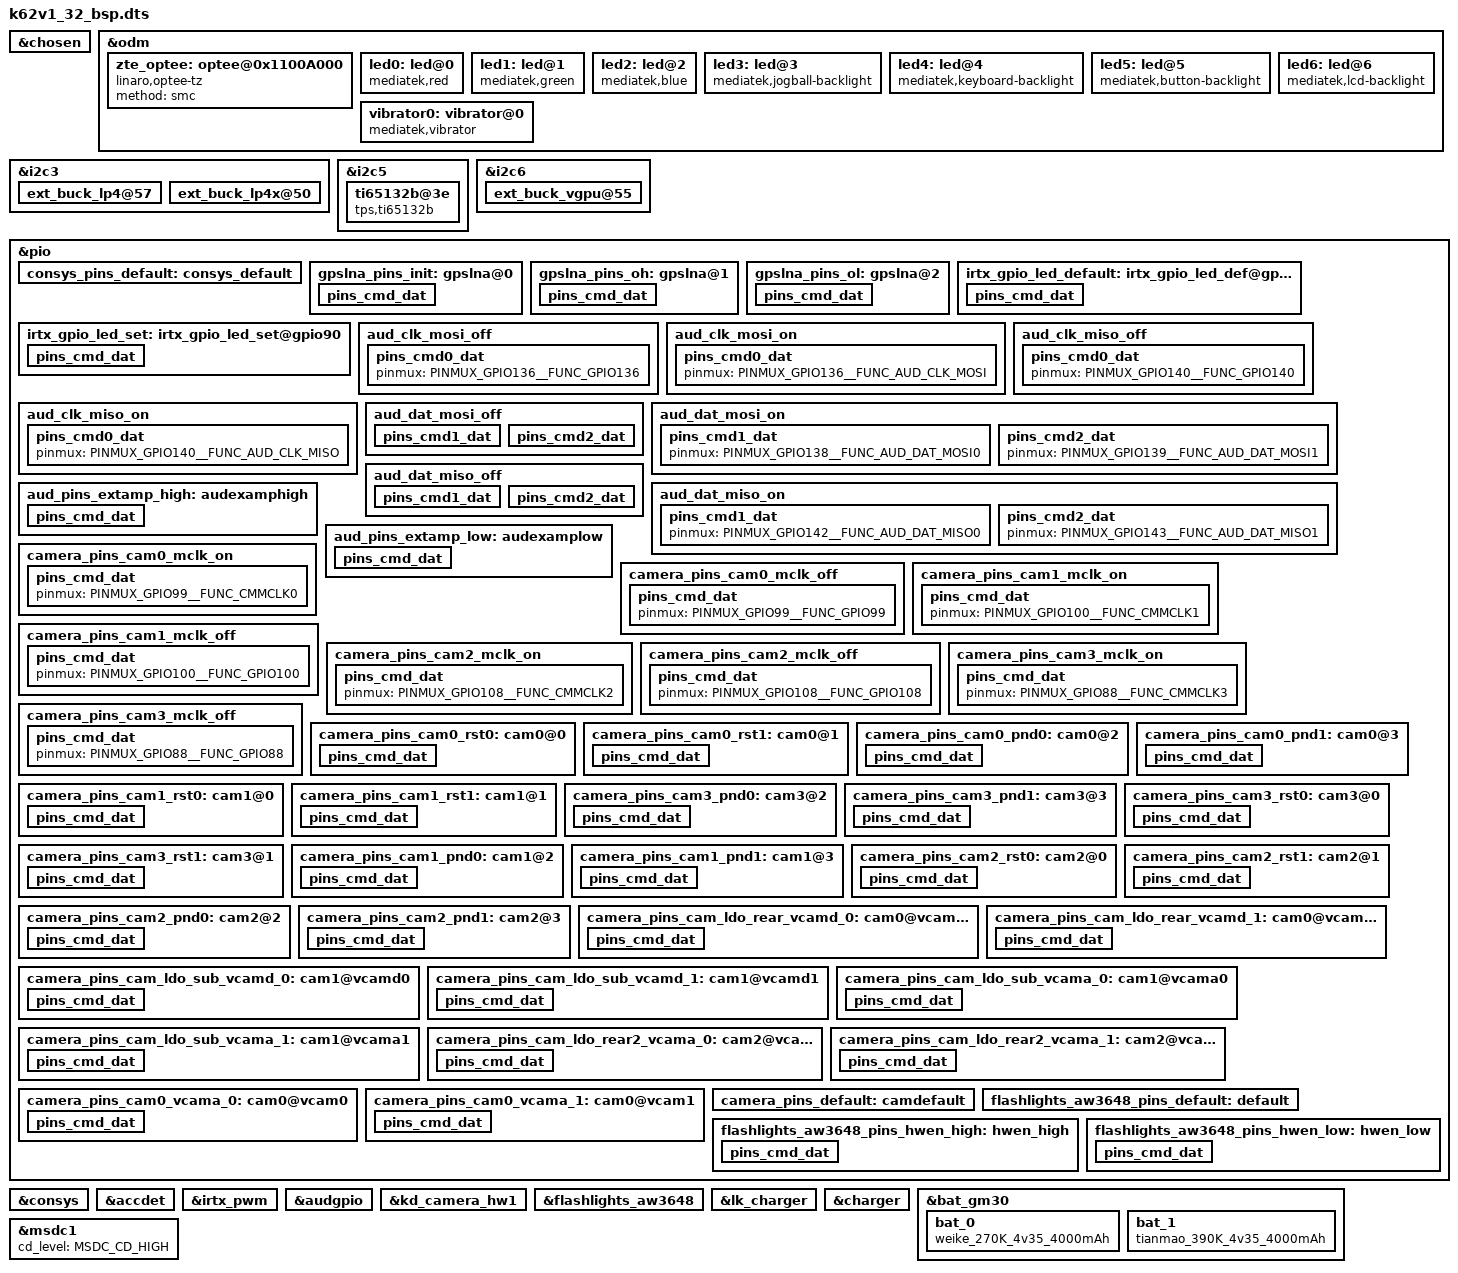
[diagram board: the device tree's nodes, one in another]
#include <dt-bindings/interrupt-controller/arm-gic.h>
#include <dt-bindings/interrupt-controller/irq.h>
#include <dt-bindings/pinctrl/mt6765-pinfunc.h>
#include <dt-bindings/mmc/mt6765-msdc.h>
#include <dt-bindings/clock/mt6765-clk.h>

/dts-v1/;
/plugin/;

#include "touchscreen_scorpio.dtsi"

/* chosen */
&chosen {

	/* fpga may has no lk, we need to specify display info here */
	/* fb buffer is reserved using this dts by memory node above */
	atag,videolfb-fb_base_h = <0x0>;
	atag,videolfb-fb_base_l = <0x5e605000>;
	atag,videolfb-islcmfound = <1>;
	/* because no lk, so lcm is not inited */
	atag,videolfb-islcm_inited = <0>;
	atag,videolfb-fps= <6000>;
	atag,videolfb-vramSize= <0x017bb000>;
	atag,videolfb-lcmname= "nt35695B_fhd_dsi_cmd_auo_rt5081_drv";
};

&odm {
	zte_optee: optee@0x1100A000 {
		compatible = "linaro,optee-tz";
		method = "smc";
	};
	led0:led@0 {
		compatible = "mediatek,red";
		led_mode = <3>;
		data = <2>;
		pwm_config = <0 0 0 0 0>;
	};
	led1:led@1 {
		compatible = "mediatek,green";
		led_mode = <3>;
		data = <1>;
		pwm_config = <0 0 0 0 0>;
	};
	led2:led@2 {
		compatible = "mediatek,blue";
		led_mode = <0>;
		data = <1>;
		pwm_config = <0 0 0 0 0>;
	};
	led3:led@3 {
		compatible = "mediatek,jogball-backlight";
		led_mode = <0>;
		data = <1>;
		pwm_config = <0 0 0 0 0>;
	};
	led4:led@4 {
		compatible = "mediatek,keyboard-backlight";
		led_mode = <0>;
		data = <1>;
		pwm_config = <0 0 0 0 0>;
	};
	led5:led@5 {
		compatible = "mediatek,button-backlight";
		led_mode = <0>;
		data = <1>;
		pwm_config = <0 0 0 0 0>;
	};
	led6:led@6 {
		compatible = "mediatek,lcd-backlight";
		led_mode = <5>;
		data = <1>;
		pwm_config = <3 0 0 0 0>;
	};
	vibrator0:vibrator@0 {
		compatible = "mediatek,vibrator";
		vib_timer = <25>;
		vib_limit = <9>;
		vib_vol= <9>;



	};
};

&i2c3 {
	ext_buck_lp4@57 {
		regulator-name ="ext_buck_vdd2";
		regulator-min-microvolt = <300000>;
		regulator-max-microvolt = <1300000>;
		vsel_pin = <0>;
	};

	ext_buck_lp4x@50 {
		regulator-name ="ext_buck_vddq";
		regulator-min-microvolt = <300000>;
		regulator-max-microvolt = <1300000>;
		vsel_pin = <1>;
	};
};

&i2c5 {
	ti65132b@3e {
		compatible = "tps,ti65132b";
		reg = <0x3e>;
		tps65132,enp-gpio = <&pio 167 0x00>;
		tps65132,enn-gpio = <&pio 168 0x00>;
	};
};

&i2c6 {
	ext_buck_vgpu@55 {
		regulator-name ="ext_buck_vgpu";
		regulator-min-microvolt = <300000>;
		regulator-max-microvolt = <1300000>;
		vsel_pin = <2>;
	};
};

/* CONSYS GPIO standardization */
&pio {
	consys_pins_default: consys_default {
	};
	gpslna_pins_init: gpslna@0 {
		pins_cmd_dat {
			pinmux = <PINMUX_GPIO91__FUNC_GPIO91>;
			slew-rate = <0>;
			bias-disable;
			output-low;
		};
	};
	gpslna_pins_oh: gpslna@1 {
		pins_cmd_dat {
			pinmux = <PINMUX_GPIO91__FUNC_GPIO91>;
			slew-rate = <1>;
			output-high;
		};
	};
	gpslna_pins_ol: gpslna@2 {
		pins_cmd_dat {
			pinmux = <PINMUX_GPIO91__FUNC_GPIO91>;
			slew-rate = <1>;
			output-low;
		};
	};
};
&consys {
	pinctrl-names = "default", "gps_lna_state_init",
		"gps_lna_state_oh", "gps_lna_state_ol";
	pinctrl-0 = <&consys_pins_default>;
	pinctrl-1 = <&gpslna_pins_init>;
	pinctrl-2 = <&gpslna_pins_oh>;
	pinctrl-3 = <&gpslna_pins_ol>;
	status = "okay";
};
/* CONSYS end */

/* accdet start */
&accdet {
	accdet-mic-vol = <7>;
	headset-mode-setting = <0x500 0x500 1 0x1f0 0x800 0x800 0x20 0x44>;
	accdet-plugout-debounce = <1>;
	accdet-mic-mode = <1>;
	headset-eint-level-pol = <8>;
	headset-three-key-threshold = <0 80 200 400>;
	headset-three-key-threshold-CDD = <0 121 192 600>;
	headset-four-key-threshold = <0 58 121 192 400>;
	status = "okay";
};
/* accdet end */

/* IRTX GPIO end */
&irtx_pwm {
	pinctrl-names = "irtx_gpio_led_default", "irtx_gpio_led_set";
	pinctrl-0 = <&irtx_gpio_led_default>;
	pinctrl-1 = <&irtx_gpio_led_set>;
	status = "okay";
};
&pio {
	irtx_gpio_led_default:irtx_gpio_led_def@gpio90 {
		pins_cmd_dat {
			pinmux = <PINMUX_GPIO90__FUNC_GPIO90>;
			slew-rate = <1>;
			bias-disable;
			output-low;
			input-schmitt-enable = <0>;
		};
	};
	irtx_gpio_led_set:irtx_gpio_led_set@gpio90 {
		pins_cmd_dat {
			pinmux = <PINMUX_GPIO90__FUNC_PWM0>;
			slew-rate = <1>;
			output-high;
		};
	};
};
/* IRTX GPIO Settings -End */
/* AUDIO GPIO standardization */
&audgpio {
	pinctrl-names = "aud_clk_mosi_off",
			"aud_clk_mosi_on",
			"aud_clk_miso_off",
			"aud_clk_miso_on",
			"aud_dat_mosi_off",
			"aud_dat_mosi_on",
			"aud_dat_miso_off",
			"aud_dat_miso_on",
			"extamp-pullhigh",
			"extamp-pulllow";
	pinctrl-0 = <&aud_clk_mosi_off>;
	pinctrl-1 = <&aud_clk_mosi_on>;
	pinctrl-2 = <&aud_clk_miso_off>;
	pinctrl-3 = <&aud_clk_miso_on>;
	pinctrl-4 = <&aud_dat_mosi_off>;
	pinctrl-5 = <&aud_dat_mosi_on>;
	pinctrl-6 = <&aud_dat_miso_off>;
	pinctrl-7 = <&aud_dat_miso_on>;
	pinctrl-8 = <&aud_pins_extamp_high>;
	pinctrl-9 = <&aud_pins_extamp_low>;
	status = "okay";
};

&pio {
	aud_clk_mosi_off: aud_clk_mosi_off {
		pins_cmd0_dat {
			pinmux = <PINMUX_GPIO136__FUNC_GPIO136>;
		};
	};

	aud_clk_mosi_on: aud_clk_mosi_on {
		pins_cmd0_dat {
			pinmux = <PINMUX_GPIO136__FUNC_AUD_CLK_MOSI>;
		};
	};

	aud_clk_miso_off: aud_clk_miso_off {
		pins_cmd0_dat {
			pinmux = <PINMUX_GPIO140__FUNC_GPIO140>;
		};
	};

	aud_clk_miso_on: aud_clk_miso_on {
		pins_cmd0_dat {
			pinmux = <PINMUX_GPIO140__FUNC_AUD_CLK_MISO>;
		};
	};

	aud_dat_mosi_off: aud_dat_mosi_off {
		pins_cmd1_dat {
			pinmux = <PINMUX_GPIO138__FUNC_GPIO138>;
			input-enable;
			slew-rate = <0>;
			bias-disable;
		};
		pins_cmd2_dat {
			pinmux = <PINMUX_GPIO139__FUNC_GPIO139>;
			input-enable;
			slew-rate = <0>;
			bias-disable;
		};
	};

	aud_dat_mosi_on: aud_dat_mosi_on {
		pins_cmd1_dat {
			pinmux = <PINMUX_GPIO138__FUNC_AUD_DAT_MOSI0>;
		};
		pins_cmd2_dat {
			pinmux = <PINMUX_GPIO139__FUNC_AUD_DAT_MOSI1>;
		};
	};

	aud_dat_miso_off: aud_dat_miso_off {
		pins_cmd1_dat {
			pinmux = <PINMUX_GPIO142__FUNC_GPIO142>;
			input-enable;
			slew-rate = <0>;
			bias-disable;
		};
		pins_cmd2_dat {
			pinmux = <PINMUX_GPIO143__FUNC_GPIO143>;
			input-enable;
			slew-rate = <0>;
			bias-disable;
		};
	};

	aud_dat_miso_on: aud_dat_miso_on {
		pins_cmd1_dat {
			pinmux = <PINMUX_GPIO142__FUNC_AUD_DAT_MISO0>;
		};
		pins_cmd2_dat {
			pinmux = <PINMUX_GPIO143__FUNC_AUD_DAT_MISO1>;
		};
	};

	aud_pins_extamp_high: audexamphigh {
		pins_cmd_dat {
			pinmux = <PINMUX_GPIO159__FUNC_GPIO159>;
			slew-rate = <1>;
			output-high;
		};
	};

	aud_pins_extamp_low: audexamplow {
		pins_cmd_dat {
			pinmux = <PINMUX_GPIO159__FUNC_GPIO159>;
			slew-rate = <1>;
			output-low;
		};
	};
};
/* AUDIO end */



&pio {
	camera_pins_cam0_mclk_on: camera_pins_cam0_mclk_on {
		pins_cmd_dat {
			pinmux = <PINMUX_GPIO99__FUNC_CMMCLK0>;
		};
	};
	camera_pins_cam0_mclk_off: camera_pins_cam0_mclk_off {
		pins_cmd_dat {
			pinmux = <PINMUX_GPIO99__FUNC_GPIO99>;
		};
	};
	camera_pins_cam1_mclk_on: camera_pins_cam1_mclk_on {
		pins_cmd_dat {
			pinmux = <PINMUX_GPIO100__FUNC_CMMCLK1>;
		};
	};
	camera_pins_cam1_mclk_off: camera_pins_cam1_mclk_off {
		pins_cmd_dat {
			pinmux = <PINMUX_GPIO100__FUNC_GPIO100>;
		};
	};
	camera_pins_cam2_mclk_on: camera_pins_cam2_mclk_on {
		pins_cmd_dat {
			pinmux = <PINMUX_GPIO108__FUNC_CMMCLK2>;
		};
	};
	camera_pins_cam2_mclk_off: camera_pins_cam2_mclk_off {
		pins_cmd_dat {
			pinmux = <PINMUX_GPIO108__FUNC_GPIO108>;
		};
	};
	camera_pins_cam3_mclk_on: camera_pins_cam3_mclk_on {
		pins_cmd_dat {
			pinmux = <PINMUX_GPIO88__FUNC_CMMCLK3>;
		};
	};
	camera_pins_cam3_mclk_off: camera_pins_cam3_mclk_off {
		pins_cmd_dat {
			pinmux = <PINMUX_GPIO88__FUNC_GPIO88>;
		};
	};
	camera_pins_cam0_rst0: cam0@0 {
		pins_cmd_dat {
			pinmux = <PINMUX_GPIO101__FUNC_GPIO101>;
			slew-rate = <1>;
			output-low;
		};
	};
	camera_pins_cam0_rst1: cam0@1 {
		pins_cmd_dat {
			pinmux = <PINMUX_GPIO101__FUNC_GPIO101>;
			slew-rate = <1>;
			output-high;
		};
	};
	camera_pins_cam0_pnd0: cam0@2 {
		pins_cmd_dat {
			pinmux = <PINMUX_GPIO97__FUNC_GPIO97>;
			slew-rate = <1>;
			output-low;
		};
	};
	camera_pins_cam0_pnd1: cam0@3 {
		pins_cmd_dat {
			pinmux = <PINMUX_GPIO97__FUNC_GPIO97>;
			slew-rate = <1>;
			output-high;
		};
	};
	camera_pins_cam1_rst0: cam1@0 {
		pins_cmd_dat {
			pinmux = <PINMUX_GPIO102__FUNC_GPIO102>;
			slew-rate = <1>;
			output-low;
		};
	};
	camera_pins_cam1_rst1: cam1@1 {
		pins_cmd_dat {
			pinmux = <PINMUX_GPIO102__FUNC_GPIO102>;
			slew-rate = <1>;
			output-high;
		};
	};
	camera_pins_cam3_pnd0: cam3@2 {
		pins_cmd_dat {
			pinmux = <PINMUX_GPIO160__FUNC_GPIO160>;
			slew-rate = <1>;
			output-low;
		};
	};
	camera_pins_cam3_pnd1: cam3@3 {
		pins_cmd_dat {
			pinmux = <PINMUX_GPIO160__FUNC_GPIO160>;
			slew-rate = <1>;
			output-high;
		};
	};
	camera_pins_cam3_rst0: cam3@0 {
		pins_cmd_dat {
			pinmux = <PINMUX_GPIO87__FUNC_GPIO87>;
			slew-rate = <1>;
			output-low;
		};
	};
	camera_pins_cam3_rst1: cam3@1 {
		pins_cmd_dat {
			pinmux = <PINMUX_GPIO87__FUNC_GPIO87>;
			slew-rate = <1>;
			output-high;
		};
	};
	camera_pins_cam1_pnd0: cam1@2 {
		pins_cmd_dat {
			pinmux = <PINMUX_GPIO98__FUNC_GPIO98>;
			slew-rate = <1>;
			output-low;
		};
	};
	camera_pins_cam1_pnd1: cam1@3 {
		pins_cmd_dat {
			pinmux = <PINMUX_GPIO98__FUNC_GPIO98>;
			slew-rate = <1>;
			output-high;
		};
	};
	camera_pins_cam2_rst0: cam2@0 {
		pins_cmd_dat {
			pinmux = <PINMUX_GPIO109__FUNC_GPIO109>;
			slew-rate = <1>;
			output-low;
		};
	};
	camera_pins_cam2_rst1: cam2@1 {
		pins_cmd_dat {
			pinmux = <PINMUX_GPIO109__FUNC_GPIO109>;
			slew-rate = <1>;
			output-high;
		};
	};
	camera_pins_cam2_pnd0: cam2@2 {
		pins_cmd_dat {
			pinmux = <PINMUX_GPIO107__FUNC_GPIO107>;
			slew-rate = <1>;
			output-low;
		};
	};
	camera_pins_cam2_pnd1: cam2@3 {
		pins_cmd_dat {
			pinmux = <PINMUX_GPIO107__FUNC_GPIO107>;
			slew-rate = <1>;
			output-high;
		};
	};
	camera_pins_cam_ldo_rear_vcamd_0: cam0@vcamd0 {
		pins_cmd_dat {
			pinmux = <PINMUX_GPIO88__FUNC_GPIO88>;
			slew-rate = <1>;
			output-low;
		};
	};
	camera_pins_cam_ldo_rear_vcamd_1: cam0@vcamd1 {
		pins_cmd_dat {
			pinmux = <PINMUX_GPIO88__FUNC_GPIO88>;
			slew-rate = <1>;
			output-high;
		};
	};
	camera_pins_cam_ldo_sub_vcamd_0: cam1@vcamd0 {
		pins_cmd_dat {
			pinmux = <PINMUX_GPIO175__FUNC_GPIO175>;
			slew-rate = <1>;
			output-low;
		};
	};
	camera_pins_cam_ldo_sub_vcamd_1: cam1@vcamd1 {
		pins_cmd_dat {
			pinmux = <PINMUX_GPIO175__FUNC_GPIO175>;
			slew-rate = <1>;
			output-high;
		};
	};
	camera_pins_cam_ldo_sub_vcama_0: cam1@vcama0 {
		pins_cmd_dat {
			pinmux = <PINMUX_GPIO175__FUNC_GPIO175>;
			slew-rate = <1>;
			output-low;
		};
	};
	camera_pins_cam_ldo_sub_vcama_1: cam1@vcama1 {
		pins_cmd_dat {
			pinmux = <PINMUX_GPIO175__FUNC_GPIO175>;
			slew-rate = <1>;
			output-high;
		};
	};
	camera_pins_cam_ldo_rear2_vcama_0: cam2@vcama0 {
		pins_cmd_dat {
			pinmux = <PINMUX_GPIO90__FUNC_GPIO90>;
			slew-rate = <1>;
			output-low;
		};
	};
	camera_pins_cam_ldo_rear2_vcama_1: cam2@vcama1 {
		pins_cmd_dat {
			pinmux = <PINMUX_GPIO90__FUNC_GPIO90>;
			slew-rate = <1>;
			output-high;
		};
	};
	camera_pins_cam0_vcama_0: cam0@vcam0 {
		pins_cmd_dat {
			pinmux = <PINMUX_GPIO176__FUNC_GPIO176>;
			slew-rate = <1>;
			output-low;
		};
	};
	camera_pins_cam0_vcama_1: cam0@vcam1 {
		pins_cmd_dat {
			pinmux = <PINMUX_GPIO176__FUNC_GPIO176>;
			slew-rate = <1>;
			output-high;
		};
	};
	camera_pins_default: camdefault {
	};

};

&kd_camera_hw1 {
	pinctrl-names = "default",
			"cam0_rst0",
			"cam0_rst1",
			"cam0_pnd0",
			"cam0_pnd1",
			"cam1_rst0",
			"cam1_rst1",
			"cam1_pnd0",
			"cam1_pnd1",
			"cam2_rst0",
			"cam2_rst1",
			"cam2_pnd0",
			"cam2_pnd1",
			"cam0_vcamd_on",
			"cam0_vcamd_off",
			"cam_ldo_sub_vcamd_1",
			"cam_ldo_sub_vcamd_0",
			"cam_ldo_sub_vcama_1",
			"cam_ldo_sub_vcama_0",
			"cam2_vcama_on",
			"cam2_vcama_off",
			"cam0_mclk_on",
			"cam0_mclk_off",
			"cam1_mclk_on",
			"cam1_mclk_off",
			"cam2_mclk_on",
			"cam2_mclk_off",
			"cam_ldo_vcama_0",
			"cam_ldo_vcama_1",
			"cam3_pnd1",
			"cam3_pnd0",
			"cam3_rst1",
			"cam3_rst0",
			"cam3_mclk_on",
			"cam3_mclk_off";

	pinctrl-0 = <&camera_pins_default>;
	pinctrl-1 = <&camera_pins_cam0_rst0>;
	pinctrl-2 = <&camera_pins_cam0_rst1>;
	pinctrl-3 = <&camera_pins_cam0_pnd0>;
	pinctrl-4 = <&camera_pins_cam0_pnd1>;
	pinctrl-5 = <&camera_pins_cam1_rst0>;
	pinctrl-6 = <&camera_pins_cam1_rst1>;
	pinctrl-7 = <&camera_pins_cam1_pnd0>;
	pinctrl-8 = <&camera_pins_cam1_pnd1>;
	pinctrl-9 = <&camera_pins_cam2_rst0>;
	pinctrl-10 = <&camera_pins_cam2_rst1>;
	pinctrl-11 = <&camera_pins_cam2_pnd0>;
	pinctrl-12 = <&camera_pins_cam2_pnd1>;
	pinctrl-13 = <&camera_pins_cam_ldo_rear_vcamd_1>;
	pinctrl-14 = <&camera_pins_cam_ldo_rear_vcamd_0>;
	pinctrl-15 = <&camera_pins_cam_ldo_sub_vcamd_1>;
	pinctrl-16 = <&camera_pins_cam_ldo_sub_vcamd_0>;
	pinctrl-17 = <&camera_pins_cam_ldo_sub_vcama_1>;
	pinctrl-18 = <&camera_pins_cam_ldo_sub_vcama_0>;
	pinctrl-19 = <&camera_pins_cam_ldo_rear2_vcama_1>;
	pinctrl-20 = <&camera_pins_cam_ldo_rear2_vcama_0>;
	pinctrl-21 = <&camera_pins_cam0_mclk_on>;
	pinctrl-22 = <&camera_pins_cam0_mclk_off>;
	pinctrl-23 = <&camera_pins_cam1_mclk_on>;
	pinctrl-24 = <&camera_pins_cam1_mclk_off>;
	pinctrl-25 = <&camera_pins_cam2_mclk_on>;
	pinctrl-26 = <&camera_pins_cam2_mclk_off>;
	pinctrl-27 = <&camera_pins_cam0_vcama_0>;
	pinctrl-28 = <&camera_pins_cam0_vcama_1>;
	pinctrl-29 = <&camera_pins_cam3_pnd1>;
	pinctrl-30 = <&camera_pins_cam3_pnd0>;
	pinctrl-31 = <&camera_pins_cam3_rst1>;
	pinctrl-32 = <&camera_pins_cam3_rst0>;
	pinctrl-33 = <&camera_pins_cam3_mclk_on>;
	pinctrl-34 = <&camera_pins_cam3_mclk_off>;
	status = "okay";
};

/*Flashlight GPIO begin*/
&pio {
	flashlights_aw3648_pins_default:default {
	};
	flashlights_aw3648_pins_hwen_high:hwen_high {
		pins_cmd_dat {
			pinmux = <PINMUX_GPIO150__FUNC_GPIO150>;
			slew-rate = <1>;
			output-high;
		};
	};
	flashlights_aw3648_pins_hwen_low:hwen_low {
		pins_cmd_dat {
			pinmux = <PINMUX_GPIO150__FUNC_GPIO150>;
			slew-rate = <1>;
			output-low;
		};
	};
};
&flashlights_aw3648 {
	pinctrl-names = "default", "hwen_high", "hwen_low";
	pinctrl-0 = <&flashlights_aw3648_pins_default>;
	pinctrl-1 = <&flashlights_aw3648_pins_hwen_high>;
	pinctrl-2 = <&flashlights_aw3648_pins_hwen_low>;
	status = "okay";
};

&lk_charger {
	ac_charger_current = <1500000>;
	ac_charger_input_current = <1300000>;
	ta_ac_charger_current = <1200000>;

	/* battery temperature protection */
	temp_t4_threshold = <55>;
	temp_t3_threshold = <45>;
	temp_t1_threshold = <15>;
};

&charger {
	enable_sw_jeita;
	battery_cv = <4352000>;
	ac_charger_input_current = <2000000>;
	ac_charger_current = <2000000>;
	charging_host_charger_current = <1500000>;
	ta_ac_charger_current = <2000000>;

	/* sw jeita */
	jeita_temp_above_t4_cv = <4100000>;
	jeita_temp_t3_to_t4_cv = <4100000>;
	jeita_temp_t2_to_t3_cv = <4352000>;
	jeita_temp_t1_to_t2_cv = <4352000>;
	jeita_temp_t0_to_t1_cv = <4352000>;
	jeita_temp_below_t0_cv = <4100000>;

	jeita_temp_above_t4_chg_current = <0>;
	jeita_temp_t3_to_t4_chg_current = <1500000>;
	jeita_temp_t2_to_t3_chg_current = <2000000>;
	jeita_temp_t1_to_t2_chg_current = <1000000>;
	jeita_temp_t0_to_t1_chg_current = <1000000>;
	jeita_temp_below_t0_chg_current = <0>;

	temp_t4_thres = <55>;
	temp_t4_thres_minus_x_degree = <53>;
	temp_t3_thres = <45>;
	temp_t3_thres_minus_x_degree = <43>;
	temp_t2_thres = <15>;
	temp_t2_thres_plus_x_degree = <17>;
	temp_t1_thres = <1>;
	temp_t1_thres_plus_x_degree = <3>;
	temp_t0_thres = <1>;
	temp_t0_thres_plus_x_degree = <3>;
	temp_neg_10_thres = <1>;

	/* battery temperature protection */
	enable_min_charge_temp;
	min_charge_temp = <0>;
	min_charge_temp_plus_x_degree = <3>;
	max_charge_temp = <55>;
	max_charge_temp_minus_x_degree = <52>;
};

&bat_gm30 {

	BATT_FULL_DESIGN_CAPACITY = <(4000)>;
	SHUTDOWN_1_TIME = <(20)>;
	R_FG_VALUE = <(10)>;
	EMBEDDED_SEL = <(1)>;
	CAR_TUNE_VALUE = <(100)>;
	KEEP_100_PERCENT = <(2)>;

	g_FG_PSEUDO100_T0 = <(99)>;
	g_FG_PSEUDO100_T1 = <(99)>;
	g_FG_PSEUDO100_T2 = <(99)>;
	g_FG_PSEUDO100_T3 = <(99)>;
	g_FG_PSEUDO100_T4 = <(99)>;

	#include "../bat_setting/mt6765_battery_table_ext_4000mah_P662S02_weike.dtsi"
	#include "../bat_setting/mt6765_battery_table_ext_4000mah_P662S02_tianmao.dtsi"

	/* bat_id_pull_up_r = 180K bat_id_pull_up_volt = 1.8V */
	bat_num = <(2)>;
	bat_0 {
		compatible = "weike_270K_4v35_4000mAh";
		bat_type = "bat0_weike_270K_4v35_4000mAh";
		bat_id_uv = <(1080000)>;
	};

	bat_1 {
		compatible = "tianmao_390K_4v35_4000mAh";
		bat_type = "bat1_tianmao_390K_4v35_4000mAh";
		bat_id_uv = <(1231579)>;
	};
};

&msdc1 {
	cd_level = /bits/ 8 <MSDC_CD_HIGH>;
};

#include <k62v1_32_bsp_scorpio/cust.dtsi>
#include "sar_scorpio.dtsi"
/*End of this file, DO NOT ADD ANYTHING HERE*/
